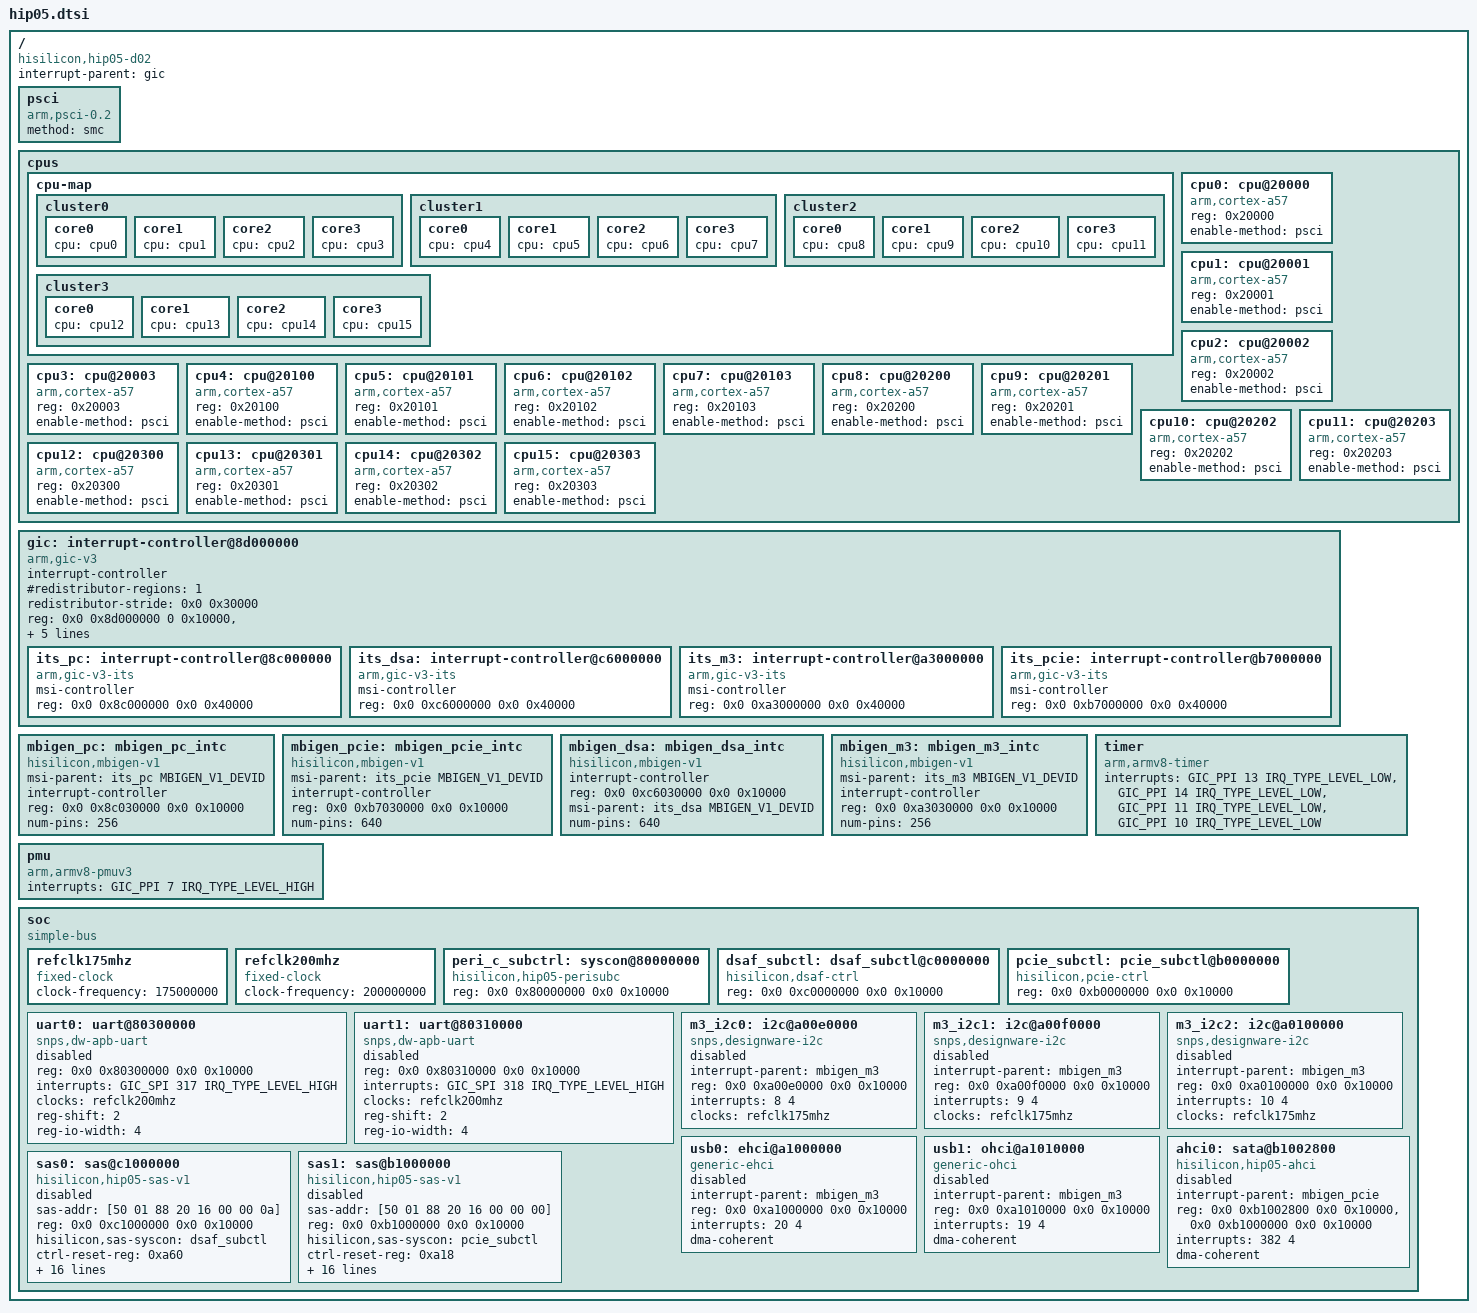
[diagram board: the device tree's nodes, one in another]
/**
 * dts file for Hisilicon D02 Development Board
 *
 * Copyright (C) 2014,2015 Hisilicon Ltd.
 *
 * This program is free software; you can redistribute it and/or modify
 * it under the terms of the GNU General Public License version 2 as
 * publishhed by the Free Software Foundation.
 *
 */

#include <dt-bindings/interrupt-controller/arm-gic.h>
#include <dt-bindings/interrupt-controller/mbigen-v1.h>
/ {
	compatible = "hisilicon,hip05-d02";
	interrupt-parent = <&gic>;
	#address-cells = <2>;
	#size-cells = <2>;

	psci {
		compatible = "arm,psci-0.2";
		method = "smc";
	};

	cpus {
		#address-cells = <1>;
		#size-cells = <0>;

		cpu-map {
			cluster0 {
				core0 {
					cpu = <&cpu0>;
				};
				core1 {
					cpu = <&cpu1>;
				};
				core2 {
					cpu = <&cpu2>;
				};
				core3 {
					cpu = <&cpu3>;
				};
			};
			cluster1 {
				core0 {
					cpu = <&cpu4>;
				};
				core1 {
					cpu = <&cpu5>;
				};
				core2 {
					cpu = <&cpu6>;
				};
				core3 {
					cpu = <&cpu7>;
				};
			};
			cluster2 {
				core0 {
					cpu = <&cpu8>;
				};
				core1 {
					cpu = <&cpu9>;
				};
				core2 {
					cpu = <&cpu10>;
				};
				core3 {
					cpu = <&cpu11>;
				};
			};
			cluster3 {
				core0 {
					cpu = <&cpu12>;
				};
				core1 {
					cpu = <&cpu13>;
				};
				core2 {
					cpu = <&cpu14>;
				};
				core3 {
					cpu = <&cpu15>;
				};
			};
		};

		cpu0: cpu@20000 {
			device_type = "cpu";
			compatible = "arm,cortex-a57", "arm,armv8";
			reg = <0x20000>;
			enable-method = "psci";
		};

		cpu1: cpu@20001 {
			device_type = "cpu";
			compatible = "arm,cortex-a57", "arm,armv8";
			reg = <0x20001>;
			enable-method = "psci";
		};

		cpu2: cpu@20002 {
			device_type = "cpu";
			compatible = "arm,cortex-a57", "arm,armv8";
			reg = <0x20002>;
			enable-method = "psci";
		};

		cpu3: cpu@20003 {
			device_type = "cpu";
			compatible = "arm,cortex-a57", "arm,armv8";
			reg = <0x20003>;
			enable-method = "psci";
		};

		cpu4: cpu@20100 {
			device_type = "cpu";
			compatible = "arm,cortex-a57", "arm,armv8";
			reg = <0x20100>;
			enable-method = "psci";
		};

		cpu5: cpu@20101 {
			device_type = "cpu";
			compatible = "arm,cortex-a57", "arm,armv8";
			reg = <0x20101>;
			enable-method = "psci";
		};

		cpu6: cpu@20102 {
			device_type = "cpu";
			compatible = "arm,cortex-a57", "arm,armv8";
			reg = <0x20102>;
			enable-method = "psci";
		};

		cpu7: cpu@20103 {
			device_type = "cpu";
			compatible = "arm,cortex-a57", "arm,armv8";
			reg = <0x20103>;
			enable-method = "psci";
		};

		cpu8: cpu@20200 {
			device_type = "cpu";
			compatible = "arm,cortex-a57", "arm,armv8";
			reg = <0x20200>;
			enable-method = "psci";
		};

		cpu9: cpu@20201 {
			device_type = "cpu";
			compatible = "arm,cortex-a57", "arm,armv8";
			reg = <0x20201>;
			enable-method = "psci";
		};

		cpu10: cpu@20202 {
			device_type = "cpu";
			compatible = "arm,cortex-a57", "arm,armv8";
			reg = <0x20202>;
			enable-method = "psci";
		};

		cpu11: cpu@20203 {
			device_type = "cpu";
			compatible = "arm,cortex-a57", "arm,armv8";
			reg = <0x20203>;
			enable-method = "psci";
		};

		cpu12: cpu@20300 {
			device_type = "cpu";
			compatible = "arm,cortex-a57", "arm,armv8";
			reg = <0x20300>;
			enable-method = "psci";
		};

		cpu13: cpu@20301 {
			device_type = "cpu";
			compatible = "arm,cortex-a57", "arm,armv8";
			reg = <0x20301>;
			enable-method = "psci";
		};

		cpu14: cpu@20302 {
			device_type = "cpu";
			compatible = "arm,cortex-a57", "arm,armv8";
			reg = <0x20302>;
			enable-method = "psci";
		};

		cpu15: cpu@20303 {
			device_type = "cpu";
			compatible = "arm,cortex-a57", "arm,armv8";
			reg = <0x20303>;
			enable-method = "psci";
		};
	};

	gic: interrupt-controller@8d000000 {
		compatible = "arm,gic-v3";
                #interrupt-cells = <3>;
                #address-cells = <2>;
                #size-cells = <2>;
                ranges;
                interrupt-controller;
                #redistributor-regions = <1>;
                redistributor-stride = <0x0 0x30000>;
		reg = <0x0 0x8d000000 0 0x10000>,	/* GICD */
		      <0x0 0x8d100000 0 0x300000>,	/* GICR */
		      <0x0 0xfe000000 0 0x10000>,	/* GICC */
		      <0x0 0xfe010000 0 0x10000>,       /* GICH */
		      <0x0 0xfe020000 0 0x10000>;       /* GICV */
		interrupts = <GIC_PPI 9 IRQ_TYPE_LEVEL_HIGH>;

		its_pc: interrupt-controller@8c000000 {
			compatible = "arm,gic-v3-its";
			msi-controller;
			#msi-cells = <1>;
			reg = <0x0 0x8c000000 0x0 0x40000>;
		};

		its_dsa: interrupt-controller@c6000000 {
			compatible = "arm,gic-v3-its";
			msi-controller;
			#msi-cells = <1>;
			reg = <0x0 0xc6000000 0x0 0x40000>;
		};

		its_m3: interrupt-controller@a3000000 {
			compatible = "arm,gic-v3-its";
			msi-controller;
			#msi-cells = <1>;
			reg = <0x0 0xa3000000 0x0 0x40000>;
		};

		its_pcie: interrupt-controller@b7000000 {
			compatible = "arm,gic-v3-its";
			msi-controller;
			#msi-cells = <1>;
			reg = <0x0 0xb7000000 0x0 0x40000>;
		};
	};

	mbigen_pc: mbigen_pc_intc {
		compatible = "hisilicon,mbigen-v1";
		msi-parent = <&its_pc MBIGEN_V1_DEVID>;
		interrupt-controller;
		#interrupt-cells = <2>;
		reg = <0x0 0x8c030000 0x0 0x10000>;
		num-pins = <256>;
	};

	mbigen_pcie: mbigen_pcie_intc {
		compatible = "hisilicon,mbigen-v1";
		msi-parent = <&its_pcie MBIGEN_V1_DEVID>;
		interrupt-controller;
		#interrupt-cells = <2>;
		reg = <0x0 0xb7030000 0x0 0x10000>;
		num-pins = <640>;
	};

	mbigen_dsa:mbigen_dsa_intc{
		compatible = "hisilicon,mbigen-v1";
		interrupt-controller;
		#interrupt-cells = <2>;
		reg = <0x0 0xc6030000 0x0 0x10000>;
		msi-parent = <&its_dsa MBIGEN_V1_DEVID>;
		num-pins = <640>;
	};

	mbigen_m3:mbigen_m3_intc {
		compatible = "hisilicon,mbigen-v1";
		msi-parent = <&its_m3 MBIGEN_V1_DEVID>;
		interrupt-controller;
		#interrupt-cells = <2>;
		reg = <0x0 0xa3030000 0x0 0x10000>;
		num-pins = <256>;
	};

	timer {
		compatible = "arm,armv8-timer";
		interrupts = <GIC_PPI 13 IRQ_TYPE_LEVEL_LOW>,
			     <GIC_PPI 14 IRQ_TYPE_LEVEL_LOW>,
			     <GIC_PPI 11 IRQ_TYPE_LEVEL_LOW>,
			     <GIC_PPI 10 IRQ_TYPE_LEVEL_LOW>;
	};

	pmu {
		compatible = "arm,armv8-pmuv3";
		interrupts = <GIC_PPI 7 IRQ_TYPE_LEVEL_HIGH>;
	};

	soc {
		compatible = "simple-bus";
		#address-cells = <2>;
		#size-cells = <2>;
		ranges;

		refclk175mhz: refclk175mhz {
			compatible = "fixed-clock";
			#clock-cells = <0>;
			clock-frequency = <175000000>;
		};

		refclk200mhz: refclk200mhz {
			compatible = "fixed-clock";
			#clock-cells = <0>;
			clock-frequency = <200000000>;
		};

		peri_c_subctrl: syscon@80000000 {
			compatible = "hisilicon,hip05-perisubc", "syscon";
			reg = < 0x0 0x80000000 0x0 0x10000>;
		};

		dsaf_subctl: dsaf_subctl@c0000000 {
			compatible = "hisilicon,dsaf-ctrl", "syscon";
			reg = <0x0 0xc0000000 0x0 0x10000>;
		};

		pcie_subctl: pcie_subctl@b0000000 {
			compatible = "hisilicon,pcie-ctrl", "syscon";
			reg = <0x0 0xb0000000 0x0 0x10000>;
		};

		uart0: uart@80300000 {
			compatible = "snps,dw-apb-uart";
			reg = <0x0 0x80300000 0x0 0x10000>;
			interrupts = <GIC_SPI 317 IRQ_TYPE_LEVEL_HIGH>;
			clocks = <&refclk200mhz>;
			clock-names = "apb_pclk";
			reg-shift = <2>;
			reg-io-width = <4>;
			status = "disabled";
		};

		uart1: uart@80310000 {
			compatible = "snps,dw-apb-uart";
			reg = <0x0 0x80310000 0x0 0x10000>;
			interrupts = <GIC_SPI 318 IRQ_TYPE_LEVEL_HIGH>;
			clocks = <&refclk200mhz>;
			clock-names = "apb_pclk";
			reg-shift = <2>;
			reg-io-width = <4>;
			status = "disabled";
		};

		m3_i2c0: i2c@a00e0000 {
			#address-cells = <1>;
			#size-cells = <0>;
			compatible = "snps,designware-i2c";
			interrupt-parent = <&mbigen_m3>;
			reg = <0x0 0xa00e0000 0x0 0x10000>;
			interrupts = <8 4>;
			clocks = <&refclk175mhz>;
			status = "disabled";
		};

		m3_i2c1: i2c@a00f0000 {
			#address-cells = <1>;
			#size-cells = <0>;
			compatible = "snps,designware-i2c";
			interrupt-parent = <&mbigen_m3>;
			reg = <0x0 0xa00f0000 0x0 0x10000>;
			interrupts = <9 4>;
			clocks = <&refclk175mhz>;
			status = "disabled";
		};

		m3_i2c2: i2c@a0100000 {
			#address-cells = <1>;
			#size-cells = <0>;
			compatible = "snps,designware-i2c";
			interrupt-parent = <&mbigen_m3>;
			reg = <0x0 0xa0100000 0x0 0x10000>;
			interrupts = <10 4>;
			clocks = <&refclk175mhz>;
			status = "disabled";
		};

		usb0: ehci@a1000000 {
			compatible = "generic-ehci";
			interrupt-parent = <&mbigen_m3>;
			reg = <0x0 0xa1000000 0x0 0x10000>;
			interrupts = <20 4>;
			dma-coherent;
			status = "disabled";
		};

		usb1: ohci@a1010000 {
			compatible = "generic-ohci";
			interrupt-parent = <&mbigen_m3>;
			reg = <0x0 0xa1010000 0x0 0x10000>;
			interrupts = <19 4>;
			dma-coherent;
			status = "disabled";
		};

		ahci0: sata@b1002800 {
			compatible = "hisilicon,hip05-ahci";
			interrupt-parent = <&mbigen_pcie>;
			reg = <0x0 0xb1002800 0x0 0x10000>,
			      <0x0 0xb1000000 0x0 0x10000>;
			interrupts = <382 4>;
			dma-coherent;
			status = "disabled";
		};

		sas0: sas@c1000000 {
			compatible = "hisilicon,hip05-sas-v1";
			sas-addr = [50 01 88 20 16 00 00 0a];
			reg = <0x0 0xc1000000 0x0 0x10000>;
			hisilicon,sas-syscon = <&dsaf_subctl>;
			ctrl-reset-reg = <0xa60>;
			ctrl-reset-sts-reg = <0x5a30>;
			ctrl-clock-ena-reg = <0x338>;
			queue-count = <32>;
			phy-count = <8>;
			dma-coherent;
			interrupt-parent = <&mbigen_dsa>;
			interrupts = <259 4>, <263 4>,<264 4>,/* phy irq(0~79) */
					<269 4>,<273 4>,<274 4>,/* phy irq(0~79) */
					<279 4>,<283 4>,<284 4>,/* phy irq(0~79) */
					<289 4>,<293 4>,<294 4>,/* phy irq(0~79) */
					<299 4>,<303 4>,<304 4>,/* phy irq(0~79) */
					<309 4>,<313 4>,<314 4>,/* phy irq(0~79) */
					<319 4>,<323 4>,<324 4>,/* phy irq(0~79) */
					<329 4>,<333 4>,<334 4>,/* phy irq(0~79) */
					<336 1>,<337 1>,<338 1>,<339 1>,<340 1>,
					<341 1>,<342 1>,<343 1>,/* cq irq (80~111) */
					<344 1>,<345 1>,<346 1>,<347 1>,<348 1>,
					<349 1>,<350 1>,<351 1>,/* cq irq (80~111) */
					<352 1>,<353 1>,<354 1>,<355 1>,<356 1>,
					<357 1>,<358 1>,<359 1>,/* cq irq (80~111) */
					<360 1>,<361 1>,<362 1>,<363 1>,<364 1>,
					<365 1>,<366 1>,<367 1>,/* cq irq (80~111) */
					<376 4>,/* chip fatal error irq(120) */
					<381 4>;/* chip fatal error irq(125) */
			status = "disabled";
		};

		sas1: sas@b1000000 {
			compatible = "hisilicon,hip05-sas-v1";
			sas-addr = [50 01 88 20 16 00 00 00];
			reg = <0x0 0xb1000000 0x0 0x10000>;
			hisilicon,sas-syscon = <&pcie_subctl>;
			ctrl-reset-reg = <0xa18>;
			ctrl-reset-sts-reg = <0x5a0c>;
			ctrl-clock-ena-reg = <0x318>;
			queue-count = <32>;
			phy-count = <8>;
			dma-coherent;
			interrupt-parent = <&mbigen_pcie>;
			interrupts = <259 4>,<263 4>,<264 4>,/* phy irq(0~79) */
					<269 4>,<273 4>,<274 4>,/* phy irq(0~79) */
					<279 4>,<283 4>,<284 4>,/* phy irq(0~79) */
					<289 4>,<293 4>,<294 4>,/* phy irq(0~79) */
					<299 4>,<303 4>,<304 4>,/* phy irq(0~79) */
					<309 4>,<313 4>,<314 4>,/* phy irq(0~79) */
					<319 4>,<323 4>,<324 4>,/* phy irq(0~79) */
					<329 4>,<333 4>,<334 4>,/* phy irq(0~79) */
					<336 1>,<337 1>,<338 1>,<339 1>,<340 1>,
					<341 1>,<342 1>,<343 1>,/* cq irq (80~111) */
					<344 1>,<345 1>,<346 1>,<347 1>,<348 1>,
					<349 1>,<350 1>,<351 1>,/* cq irq (80~111) */
					<352 1>,<353 1>,<354 1>,<355 1>,<356 1>,
					<357 1>,<358 1>,<359 1>,/* cq irq (80~111) */
					<360 1>,<361 1>,<362 1>,<363 1>,<364 1>,
					<365 1>,<366 1>,<367 1>,/* cq irq (80~111) */
					<376 4>,/* chip fatal error irq(120) */
					<381 4>;/* chip fatal error irq(125) */
			status = "disabled";
		};
	};
};
